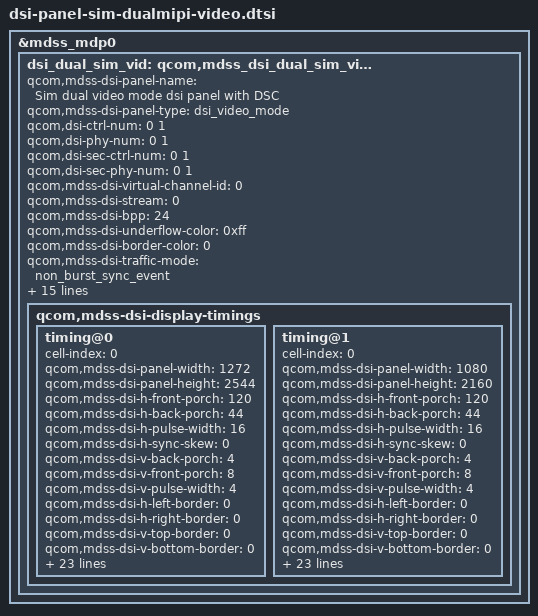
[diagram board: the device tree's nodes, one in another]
&mdss_mdp0 {
	dsi_dual_sim_vid: qcom,mdss_dsi_dual_sim_video {
		qcom,mdss-dsi-panel-name = "Sim dual video mode dsi panel with DSC";
		qcom,mdss-dsi-panel-type = "dsi_video_mode";

		qcom,dsi-ctrl-num = <0 1>;
		qcom,dsi-phy-num = <0 1>;
		qcom,dsi-sec-ctrl-num = <0 1>;
		qcom,dsi-sec-phy-num = <0 1>;
		qcom,mdss-dsi-virtual-channel-id = <0>;
		qcom,mdss-dsi-stream = <0>;
		qcom,mdss-dsi-bpp = <24>;
		qcom,mdss-dsi-underflow-color = <0xff>;
		qcom,mdss-dsi-border-color = <0>;
		qcom,mdss-dsi-traffic-mode = "non_burst_sync_event";
		qcom,mdss-dsi-bllp-eof-power-mode;
		qcom,mdss-dsi-bllp-power-mode;
		qcom,mdss-dsi-panel-broadcast-mode;
		qcom,mdss-dsi-lane-0-state;
		qcom,mdss-dsi-lane-1-state;
		qcom,mdss-dsi-lane-2-state;
		qcom,mdss-dsi-lane-3-state;
		qcom,mdss-dsi-bl-max-level = <4095>;
		qcom,mdss-dsi-dma-trigger = "trigger_sw";
		qcom,mdss-dsi-mdp-trigger = "none";
		qcom,mdss-dsi-reset-sequence = <1 20>, <0 200>, <1 20>;
		qcom,panel-ack-disabled;
		qcom,qsync-enable;
		qcom,mdss-dsi-qsync-min-refresh-rate = <45>;

		qcom,mdss-dsi-display-timings {
			timing@0 {
				cell-index = <0>;
				qcom,mdss-dsi-panel-width = <1272>;
				qcom,mdss-dsi-panel-height = <2544>;
				qcom,mdss-dsi-h-front-porch = <120>;
				qcom,mdss-dsi-h-back-porch = <44>;
				qcom,mdss-dsi-h-pulse-width = <16>;
				qcom,mdss-dsi-h-sync-skew = <0>;
				qcom,mdss-dsi-v-back-porch = <4>;
				qcom,mdss-dsi-v-front-porch = <8>;
				qcom,mdss-dsi-v-pulse-width = <4>;
				qcom,mdss-dsi-h-left-border = <0>;
				qcom,mdss-dsi-h-right-border = <0>;
				qcom,mdss-dsi-v-top-border = <0>;
				qcom,mdss-dsi-v-bottom-border = <0>;
				qcom,mdss-dsi-h-sync-pulse = <0>;
				qcom,mdss-dsi-panel-framerate = <90>;
				qcom,mdss-dsi-on-command =
					[32 01 00 00 00 00 02 00 00];
				qcom,mdss-dsi-on-command-state = "dsi_lp_mode";
				qcom,mdss-dsi-off-command =
					[05 01 00 00 32 00 02 28 00
					05 01 00 00 78 00 02 10 00];
				qcom,mdss-dsi-off-command-state = "dsi_hs_mode";
				qcom,mdss-dsi-qsync-on-commands =
					[15 01 00 00 00 00 02 51 00];
				qcom,mdss-dsi-qsync-on-commands-state =
					"dsi_hs_mode";
				qcom,mdss-dsi-qsync-off-commands =
					[15 01 00 00 00 00 02 51 00];
				qcom,mdss-dsi-qsync-off-commands-state =
					"dsi_hs_mode";
				qcom,compression-mode = "dsc";
				qcom,mdss-dsc-slice-height = <1272>;
				qcom,mdss-dsc-slice-width = <1272>;
				qcom,mdss-dsc-slice-per-pkt = <1>;
				qcom,mdss-dsc-bit-per-component = <8>;
				qcom,mdss-dsc-bit-per-pixel = <8>;
				qcom,mdss-dsc-block-prediction-enable;
			};
			timing@1 {
				cell-index = <0>;
				qcom,mdss-dsi-panel-width = <1080>;
				qcom,mdss-dsi-panel-height = <2160>;
				qcom,mdss-dsi-h-front-porch = <120>;
				qcom,mdss-dsi-h-back-porch = <44>;
				qcom,mdss-dsi-h-pulse-width = <16>;
				qcom,mdss-dsi-h-sync-skew = <0>;
				qcom,mdss-dsi-v-back-porch = <4>;
				qcom,mdss-dsi-v-front-porch = <8>;
				qcom,mdss-dsi-v-pulse-width = <4>;
				qcom,mdss-dsi-h-left-border = <0>;
				qcom,mdss-dsi-h-right-border = <0>;
				qcom,mdss-dsi-v-top-border = <0>;
				qcom,mdss-dsi-v-bottom-border = <0>;
				qcom,mdss-dsi-h-sync-pulse = <0>;
				qcom,mdss-dsi-panel-framerate = <90>;
				qcom,mdss-dsi-on-command = [
					39 01 00 00 00 00 02 FB 01
					32 01 00 00 00 00 02 00 00];
				qcom,mdss-dsi-on-command-state = "dsi_lp_mode";
				qcom,mdss-dsi-off-command =
					[05 01 00 00 32 00 02 28 00
					05 01 00 00 78 00 02 10 00];
				qcom,mdss-dsi-off-command-state = "dsi_hs_mode";
				qcom,mdss-dsi-qsync-on-commands =
					[15 01 00 00 00 00 02 51 00];
				qcom,mdss-dsi-qsync-on-commands-state =
					"dsi_hs_mode";
				qcom,mdss-dsi-qsync-off-commands =
					[15 01 00 00 00 00 02 51 00];
				qcom,mdss-dsi-qsync-off-commands-state =
					"dsi_hs_mode";
				qcom,compression-mode = "dsc";
				qcom,mdss-dsc-slice-height = <1080>;
				qcom,mdss-dsc-slice-width = <1080>;
				qcom,mdss-dsc-slice-per-pkt = <1>;
				qcom,mdss-dsc-bit-per-component = <8>;
				qcom,mdss-dsc-bit-per-pixel = <8>;
				qcom,mdss-dsc-block-prediction-enable;
			};
		};
	};
};
